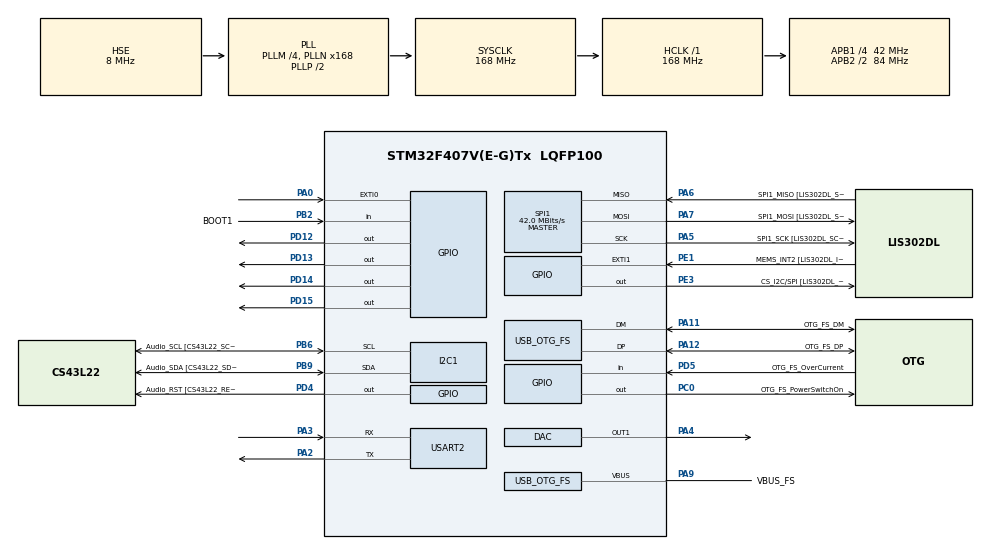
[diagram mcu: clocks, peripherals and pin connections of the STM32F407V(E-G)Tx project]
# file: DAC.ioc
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ADC1.Channel-2\#ChannelRegularConversion=ADC_CHANNEL_TEMPSENSOR
ADC1.ContinuousConvMode=ENABLE
ADC1.NbrOfConversionFlag=1
ADC1.Rank-2\#ChannelRegularConversion=1
ADC1.SamplingTime-2\#ChannelRegularConversion=ADC_SAMPLETIME_84CYCLES
ADC1.master=1
Mcu.Family=STM32F4
Mcu.Name=STM32F407V(E-G)Tx
Mcu.Package=LQFP100
NVIC.EXTI0_IRQn=true\:0\:0\:false\:true\:true\:1\:true\:true
NVIC.OTG_FS_IRQn=true\:0\:0\:false\:false\:true\:true\:true
NVIC.PriorityGroup=NVIC_PRIORITYGROUP_0
NVIC.TIM7_IRQn=true\:0\:0\:false\:true\:true\:2\:true\:true
NVIC.USART2_IRQn=true\:0\:0\:false\:true\:true\:3\:true\:true
PA0-WKUP.Signal=GPXTI0
PA10.GPIO_Label=OTG_FS_ID
PA10.GPIO_Mode=GPIO_MODE_AF_PP
PA10.GPIO_PuPd=GPIO_NOPULL
PA10.GPIO_Speed=GPIO_SPEED_FREQ_LOW
PA10.Signal=USB_OTG_FS_ID
PA11.GPIO_Label=OTG_FS_DM
PA11.GPIO_Mode=GPIO_MODE_AF_PP
PA11.GPIO_PuPd=GPIO_NOPULL
PA11.GPIO_Speed=GPIO_SPEED_FREQ_LOW
PA11.Mode=Host_Only
PA11.Signal=USB_OTG_FS_DM
PA12.GPIO_Label=OTG_FS_DP
PA12.GPIO_Mode=GPIO_MODE_AF_PP
PA12.GPIO_PuPd=GPIO_NOPULL
PA12.GPIO_Speed=GPIO_SPEED_FREQ_LOW
PA12.Mode=Host_Only
PA12.Signal=USB_OTG_FS_DP
PA13.GPIO_Label=SWDIO
PA13.Mode=Serial_Wire
PA13.Signal=SYS_JTMS-SWDIO
PA14.GPIO_Label=SWCLK
PA14.Mode=Serial_Wire
PA14.Signal=SYS_JTCK-SWCLK
PA2.Mode=Asynchronous
PA2.Signal=USART2_TX
PA3.Mode=Asynchronous
PA3.Signal=USART2_RX
PA4.Signal=COMP_DAC1_group
PA5.GPIO_Label=SPI1_SCK [LIS302DL_SCL/SPC]
PA5.GPIO_Mode=GPIO_MODE_AF_PP
PA5.GPIO_PuPd=GPIO_NOPULL
PA5.GPIO_Speed=GPIO_SPEED_FREQ_LOW
PA5.Mode=Full_Duplex_Master
PA5.Signal=SPI1_SCK
PA6.GPIO_Label=SPI1_MISO [LIS302DL_SDO]
PA6.GPIO_Mode=GPIO_MODE_AF_PP
PA6.GPIO_PuPd=GPIO_NOPULL
PA6.GPIO_Speed=GPIO_SPEED_FREQ_LOW
PA6.Mode=Full_Duplex_Master
PA6.Signal=SPI1_MISO
PA7.GPIO_Label=SPI1_MOSI [LIS302DL_SDA/SDI/SDO]
PA7.GPIO_Mode=GPIO_MODE_AF_PP
PA7.GPIO_PuPd=GPIO_NOPULL
PA7.GPIO_Speed=GPIO_SPEED_FREQ_LOW
PA7.Mode=Full_Duplex_Master
PA7.Signal=SPI1_MOSI
PA9.GPIO_Label=VBUS_FS
PA9.GPIO_Mode=GPIO_MODE_INPUT
PA9.GPIO_PuPd=GPIO_NOPULL
PA9.Mode=Activate_VBUS
PA9.Signal=USB_OTG_FS_VBUS
PB10.GPIO_Label=CLK_IN [MP45DT02_CLK]
PB10.GPIO_Mode=GPIO_MODE_AF_PP
PB10.GPIO_PuPd=GPIO_NOPULL
PB10.GPIO_Speed=GPIO_SPEED_FREQ_LOW
PB10.Signal=I2S2_CK
PB2.GPIO_Label=BOOT1
PB2.GPIO_Mode=GPIO_MODE_INPUT
PB2.GPIO_PuPd=GPIO_NOPULL
PB2.Signal=GPIO_Input
PB3.GPIO_Label=SWO
PB3.Signal=SYS_JTDO-SWO
PB6.GPIO_Label=Audio_SCL [CS43L22_SCL]
PB6.GPIO_Mode=GPIO_MODE_AF_OD
PB6.GPIO_PuPd=GPIO_NOPULL
PB6.GPIO_Speed=GPIO_SPEED_FREQ_LOW
PB6.Mode=I2C
PB6.Signal=I2C1_SCL
PB9.GPIO_Label=Audio_SDA [CS43L22_SDA]
PB9.GPIO_Mode=GPIO_MODE_AF_OD
PB9.GPIO_PuPd=GPIO_NOPULL
PB9.GPIO_Speed=GPIO_SPEED_FREQ_LOW
PB9.Mode=I2C
PB9.Signal=I2C1_SDA
PC0.GPIO_Label=OTG_FS_PowerSwitchOn
PC0.GPIO_PuPd=GPIO_NOPULL
PC0.GPIO_Speed=GPIO_SPEED_FREQ_LOW
PC0.PinState=GPIO_PIN_SET
PC0.Signal=GPIO_Output
PC10.GPIO_Label=I2S3_SCK [CS43L22_SCLK]
PC10.GPIO_Mode=GPIO_MODE_AF_PP
PC10.GPIO_PuPd=GPIO_NOPULL
PC10.GPIO_Speed=GPIO_SPEED_FREQ_LOW
PC10.Signal=I2S3_CK
PC12.GPIO_Label=I2S3_SD [CS43L22_SDIN]
PC12.GPIO_Mode=GPIO_MODE_AF_PP
PC12.GPIO_PuPd=GPIO_NOPULL
PC12.GPIO_Speed=GPIO_SPEED_FREQ_LOW
PC12.Signal=I2S3_SD
PC14-OSC32_IN.GPIO_Label=PC14-OSC32_IN
PC14-OSC32_IN.Mode=LSE-External-Oscillator
PC14-OSC32_IN.Signal=RCC_OSC32_IN
PC15-OSC32_OUT.GPIO_Label=PC15-OSC32_OUT
PC15-OSC32_OUT.Mode=LSE-External-Oscillator
PC15-OSC32_OUT.Signal=RCC_OSC32_OUT
PC3.GPIO_Label=PDM_OUT [MP45DT02_DOUT]
PC3.GPIO_Mode=GPIO_MODE_AF_PP
PC3.GPIO_PuPd=GPIO_NOPULL
PC3.GPIO_Speed=GPIO_SPEED_FREQ_LOW
PC3.Signal=I2S2_SD
PC7.GPIO_Label=I2S3_MCK [CS43L22_MCLK]
PC7.GPIO_Mode=GPIO_MODE_AF_PP
PC7.GPIO_PuPd=GPIO_NOPULL
PC7.GPIO_Speed=GPIO_SPEED_FREQ_LOW
PC7.Signal=I2S3_MCK
PD12.Signal=GPIO_Output
PD13.Signal=GPIO_Output
PD14.Signal=GPIO_Output
PD15.Signal=GPIO_Output
PD4.GPIO_Label=Audio_RST [CS43L22_RESET]
PD4.GPIO_PuPd=GPIO_NOPULL
PD4.GPIO_Speed=GPIO_SPEED_FREQ_LOW
PD4.Signal=GPIO_Output
PD5.GPIO_Label=OTG_FS_OverCurrent
PD5.GPIO_Mode=GPIO_MODE_INPUT
PD5.GPIO_PuPd=GPIO_NOPULL
PD5.Signal=GPIO_Input
PE1.GPIO_Label=MEMS_INT2 [LIS302DL_INT2]
PE1.GPIO_ModeDefaultEXTI=GPIO_MODE_EVT_RISING
PE1.GPIO_PuPd=GPIO_NOPULL
PE1.Signal=GPXTI1
PE3.GPIO_Label=CS_I2C/SPI [LIS302DL_CS_I2C/SPI]
PE3.GPIO_PuPd=GPIO_NOPULL
PE3.GPIO_Speed=GPIO_SPEED_FREQ_LOW
PE3.Signal=GPIO_Output
PH0-OSC_IN.GPIO_Label=PH0-OSC_IN
PH0-OSC_IN.Mode=HSE-External-Oscillator
PH0-OSC_IN.Signal=RCC_OSC_IN
PH1-OSC_OUT.GPIO_Label=PH1-OSC_OUT
PH1-OSC_OUT.Mode=HSE-External-Oscillator
PH1-OSC_OUT.Signal=RCC_OSC_OUT
ProjectManager.HeapSize=0x200
ProjectManager.StackSize=0x400
ProjectManager.TargetToolchain=STM32CubeIDE
RCC.48MHZClocksFreq_Value=48000000
RCC.AHBFreq_Value=168000000
RCC.APB1CLKDivider=RCC_HCLK_DIV4
RCC.APB1Freq_Value=42000000
RCC.APB1TimFreq_Value=84000000
RCC.APB2CLKDivider=RCC_HCLK_DIV2
RCC.APB2Freq_Value=84000000
RCC.APB2TimFreq_Value=168000000
RCC.CortexFreq_Value=168000000
RCC.HCLKFreq_Value=168000000
RCC.HSE_VALUE=8000000
RCC.HSI_VALUE=16000000
RCC.PLLM=4
RCC.PLLN=168
RCC.PLLQ=7
RCC.SYSCLKFreq_VALUE=168000000
RCC.SYSCLKSource=RCC_SYSCLKSOURCE_PLLCLK
RCC.VCOOutputFreq_Value=336000000
SH.COMP_DAC1_group.0=DAC_OUT1,DAC_OUT1
SPI1.BaudRatePrescaler=SPI_BAUDRATEPRESCALER_2
SPI1.BaudRatePrescaler-Full_Duplex_Master=SPI_BAUDRATEPRESCALER_2
SPI1.CalculateBaudRate=42.0 MBits/s
SPI1.CalculateBaudRate-Full_Duplex_Master=42.0 MBits/s
SPI1.Direction=SPI_DIRECTION_2LINES
SPI1.Mode=SPI_MODE_MASTER
SPI1.Mode-Full_Duplex_Master=SPI_MODE_MASTER
SPI1.VirtualType=VM_MASTER
TIM7.Period=8400-1
TIM7.Prescaler=1000-1
USART2.VirtualMode=VM_ASYNC
USB_HOST.BSP.number=1
USB_HOST.USBH_HandleTypeDef-CDC_FS=hUsbHostFS
USB_HOST.VirtualModeFS=Cdc
USB_HOST0.BSP.STBoard=false
USB_HOST0.BSP.api=Unknown
USB_HOST0.BSP.i2caddr=0
USB_HOST0.BSP.i2creg=0
USB_HOST0.BSP.instance=PC0
USB_HOST0.BSP.ip=GPIO
USB_HOST0.BSP.mode=Output
USB_HOST0.BSP.name=Drive_VBUS_FS
USB_HOST0.BSP.solution=PC0
USB_OTG_FS.VirtualMode=Host_Only
USB_OTG_FS.phy_itface=HCD_PHY_EMBEDDED
VP_ADC1_TempSens_Input.Mode=IN-TempSens
VP_TIM7_VS_ClockSourceINT.Mode=Enable_Timer
VP_USB_HOST_VS_USB_HOST_CDC_FS.Mode=CDC_FS
board=STM32F407G-DISC1

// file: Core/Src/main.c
/* USER CODE BEGIN Header */
/**
  ******************************************************************************
  * @file           : main.c
  * @brief          : Main program body
  ******************************************************************************
  * @attention
  *
  * <h2><center>&copy; Copyright (c) 2020 STMicroelectronics.
  * All rights reserved.</center></h2>
  *
  * This software component is licensed by ST under Ultimate Liberty license
  * SLA0044, the "License"; You may not use this file except in compliance with
  * the License. You may obtain a copy of the License at:
  *                             www.st.com/SLA0044
  *
  ******************************************************************************
  */
/* USER CODE END Header */

#include "main.h"
#include "adc.h"
#include "dac.h"
#include "i2c.h"
#include "spi.h"
#include "tim.h"
#include "usart.h"
#include "usb_host.h"
#include "gpio.h"

/* USER CODE BEGIN Includes */
#include <math.h>
/* USER CODE END Includes */

void SystemClock_Config(void);
static void MX_NVIC_Init(void);
void MX_USB_HOST_Process(void);

int main(void)
{

  /* MCU Configuration--------------------------------------------------------*/

  /* Reset of all peripherals, Initializes the Flash interface and the Systick. */
  HAL_Init();

  /* Configure the system clock */
  SystemClock_Config();

  /* Initialize all configured peripherals */
  MX_GPIO_Init();
  MX_I2C1_Init();
  MX_SPI1_Init();
  MX_USB_HOST_Init();
  MX_TIM7_Init();
  MX_USART2_UART_Init();
  MX_ADC1_Init();
  MX_DAC_Init();

  /* Initialize interrupts */
  MX_NVIC_Init();
  /* USER CODE BEGIN 2 */
  HAL_DAC_Start(&hdac, DAC_CHANNEL_1);
  HAL_TIM_Base_Start_IT(&htim7);
  /* USER CODE END 2 */

  /* Infinite loop */
  /* USER CODE BEGIN WHILE */
  uint16_t dacval = 0;
  while (1)
  {
//	  HAL_DAC_SetValue(&hdac, DAC_CHANNEL_1, DAC_ALIGN_12B_R, dacval);
//	  dacval++;
//	  if(dacval > 4095)	dacval = 0;
    /* USER CODE END WHILE */
    MX_USB_HOST_Process();

  }
}

void SystemClock_Config(void)
{
  RCC_OscInitTypeDef RCC_OscInitStruct = {0};
  RCC_ClkInitTypeDef RCC_ClkInitStruct = {0};

  /** Configure the main internal regulator output voltage
  */
  __HAL_RCC_PWR_CLK_ENABLE();
  __HAL_PWR_VOLTAGESCALING_CONFIG(PWR_REGULATOR_VOLTAGE_SCALE1);
  /** Initializes the CPU, AHB and APB busses clocks
  */
  RCC_OscInitStruct.OscillatorType = RCC_OSCILLATORTYPE_HSE;
  RCC_OscInitStruct.HSEState = RCC_HSE_ON;
  RCC_OscInitStruct.PLL.PLLState = RCC_PLL_ON;
  RCC_OscInitStruct.PLL.PLLSource = RCC_PLLSOURCE_HSE;
  RCC_OscInitStruct.PLL.PLLM = 4;
  RCC_OscInitStruct.PLL.PLLN = 168;
  RCC_OscInitStruct.PLL.PLLP = RCC_PLLP_DIV2;
  RCC_OscInitStruct.PLL.PLLQ = 7;
  if (HAL_RCC_OscConfig(&RCC_OscInitStruct) != HAL_OK)
  {
    Error_Handler();
  }
  /** Initializes the CPU, AHB and APB busses clocks
  */
  RCC_ClkInitStruct.ClockType = RCC_CLOCKTYPE_HCLK|RCC_CLOCKTYPE_SYSCLK
                              |RCC_CLOCKTYPE_PCLK1|RCC_CLOCKTYPE_PCLK2;
  RCC_ClkInitStruct.SYSCLKSource = RCC_SYSCLKSOURCE_PLLCLK;
  RCC_ClkInitStruct.AHBCLKDivider = RCC_SYSCLK_DIV1;
  RCC_ClkInitStruct.APB1CLKDivider = RCC_HCLK_DIV4;
  RCC_ClkInitStruct.APB2CLKDivider = RCC_HCLK_DIV2;

  if (HAL_RCC_ClockConfig(&RCC_ClkInitStruct, FLASH_LATENCY_5) != HAL_OK)
  {
    Error_Handler();
  }
}

/**
  * @brief NVIC Configuration.
  * @retval None
  */
static void MX_NVIC_Init(void)
{
  /* EXTI0_IRQn interrupt configuration */
  HAL_NVIC_SetPriority(EXTI0_IRQn, 0, 0);
  HAL_NVIC_EnableIRQ(EXTI0_IRQn);
  /* TIM7_IRQn interrupt configuration */
  HAL_NVIC_SetPriority(TIM7_IRQn, 0, 0);
  HAL_NVIC_EnableIRQ(TIM7_IRQn);
  /* USART2_IRQn interrupt configuration */
  HAL_NVIC_SetPriority(USART2_IRQn, 0, 0);
  HAL_NVIC_EnableIRQ(USART2_IRQn);
}

/* USER CODE BEGIN 4 */
void HAL_TIM_PeriodElapsedCallback(TIM_HandleTypeDef *htim)
{
	static unsigned char cnt = 0;
	if(htim->Instance == TIM7)
	{
		HAL_DAC_SetValue(&hdac, DAC_CHANNEL_1, DAC_ALIGN_12B_R, (sinf(2 * 3.141592f * 50 * cnt / 1000.f) + 1) * 2047);
		cnt++;
		if(cnt > 999)	cnt = 0;
	}

}
/* USER CODE END 4 */

void Error_Handler(void)
{
}

/************************ (C) COPYRIGHT STMicroelectronics *****END OF FILE****/
